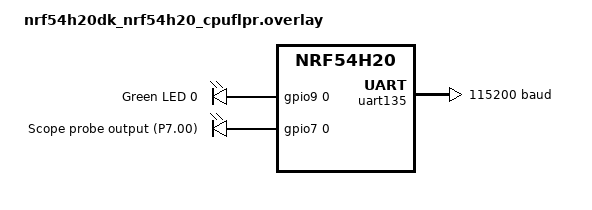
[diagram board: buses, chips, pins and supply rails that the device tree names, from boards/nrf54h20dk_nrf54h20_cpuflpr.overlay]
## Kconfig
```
# SPDX-License-Identifier: Apache-2.0

config BLINKY_BARE_METAL_GPIO
	bool "Toggle led0/probe0 by writing GPIO registers directly"
	help
	  When enabled, the blink loop drives led0 and probe0 by writing the
	  GPIO port's OUTSET/OUTCLR registers directly instead of calling
	  gpio_pin_toggle_dt(). Pin setup still uses the Zephyr GPIO API.

config BLINKY_PROBE_P7_00
	bool "Toggle P7.00 in the blink loop"
	default y
	help
	  When enabled, the blink loop toggles P7.00 (the probe0 pin) so it can
	  be probed. When disabled, P7.00 is left low. Independent of
	  BLINKY_PROBE_P9_00.

config BLINKY_FLPR_VIO
	bool "Drive P7.00 through FLPR's VIO"
	depends on SOC_NRF54H20_CPUFLPR && BLINKY_PROBE_P7_00
	help
	  Set this through SB_CONFIG_BLINKY_FLPR_VIO in sysbuild.conf, which
	  also routes P7.00 to FLPR's VIO in UICR; sysbuild overrides any value
	  set here. The blink loop then drives P7.00 with VIO CSR writes,
	  whichever toggle method is selected. P9.00 is unaffected.

config BLINKY_FLPR_VIO_DELAY_NOPS
	int "NOPs after each VIO write"
	depends on BLINKY_FLPR_VIO
	range 0 1024
	default 32
	help
	  Number of NOP instructions executed after each VIO write, i.e. once
	  for the high half and once for the low half of every pulse. Stretches
	  the few-nanosecond full-speed pulses so a logic analyzer can capture
	  them. With the default of 32, each half is roughly 100-175 ns. The
	  printed average per blink gives the actual period. Set to 0 for
	  full-speed toggling. Only affects the FLPR VIO path.

config BLINKY_PROBE_P9_00
	bool "Toggle P9.00 in the blink loop"
	help
	  When enabled, the blink loop toggles P9.00 so it can be probed. On
	  the nRF54H20 DK, P9.00 is the led0 pin, so LED0 flickers while the
	  loop runs. When disabled, P9.00 is left low. Independent of
	  BLINKY_PROBE_P7_00.

source "Kconfig.zephyr"
```

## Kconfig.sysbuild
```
# SPDX-License-Identifier: Apache-2.0

source "$(ZEPHYR_BASE)/share/sysbuild/Kconfig"

config BLINKY_FLPR_VIO
	bool "Drive P7.00 from FLPR's VIO instead of the GPIO controller"
	depends on SOC_NRF54H20_CPUFLPR
	help
	  Routes P7.00 to FLPR's VIO (CTRLSEL = VPR_GRC) through UICR, by
	  giving the vpr_launcher image a cpuflpr_vpr pinctrl entry for P7.00,
	  and sets CONFIG_BLINKY_FLPR_VIO in the application so the blink loop
	  drives P7.00 with VIO CSR writes. Also forces
	  CONFIG_BLINKY_PROBE_P7_00=y. While enabled, P7.00 cannot be driven
	  through gpio7.
```

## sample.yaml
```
sample:
  name: Blinky Sample
tests:
  sample.basic.blinky:
    tags:
      - LED
      - gpio
    filter: dt_enabled_alias_with_parent_compat("led0", "gpio-leds")
    depends_on: gpio
    harness: led
    platform_allow:
      - nrf54h20dk/nrf54h20/cpuapp
      - nrf54h20dk/nrf54h20/cpuppr
      - nrf54h20dk/nrf54h20/cpuflpr
    integration_platforms:
      - nrf54h20dk/nrf54h20/cpuapp
      - nrf54h20dk/nrf54h20/cpuppr
      - nrf54h20dk/nrf54h20/cpuflpr
```

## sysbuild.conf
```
# y: (cpuflpr only) route P7.00 to FLPR's VIO and drive it with VIO CSR writes.
# n: P7.00 is driven through the gpio7 controller.
SB_CONFIG_BLINKY_FLPR_VIO=y
```

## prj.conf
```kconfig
CONFIG_GPIO=y

# Build with -O2 instead of the default size optimization (-Os).
CONFIG_SPEED_OPTIMIZATIONS=y

# y: blink loop writes GPIO OUTSET/OUTCLR registers directly.
# n: blink loop uses gpio_pin_toggle_dt().
CONFIG_BLINKY_BARE_METAL_GPIO=y

# y: blink loop toggles P7.00 (probe0).
# n: P7.00 stays low.
CONFIG_BLINKY_PROBE_P7_00=y

# y: blink loop toggles P9.00 (the LED0 pin).
# n: P9.00/LED0 stays low.
CONFIG_BLINKY_PROBE_P9_00=n

# Explicitly ensure this image's peripheral usage (UART console, GPIO/LED,
# scope-probe pin) is emitted as UICR.PERIPHCONF entries rather than relying
# silently on the Kconfig default.
CONFIG_NRF_PERIPHCONF_GENERATE_ENTRIES=y

CONFIG_BLINKY_FLPR_VIO_DELAY_NOPS=10
```

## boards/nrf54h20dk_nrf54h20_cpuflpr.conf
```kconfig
# gpiote130 has no interrupt line on FLPR, and this app only drives outputs,
# so build the GPIO driver without GPIOTE-based interrupt support.
CONFIG_GPIO_NRFX_INTERRUPT=n

# The console is on uart135, whose IRQ cannot be routed to FLPR; keep the
# UART driver in polling mode.
CONFIG_UART_INTERRUPT_DRIVEN=n
CONFIG_UART_ASYNC_API=n
```

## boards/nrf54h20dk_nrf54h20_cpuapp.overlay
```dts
/* SPDX-License-Identifier: Apache-2.0 */

/ {
	aliases {
		probe0 = &probe0;
	};

	leds {
		/*
		 * Independent GPIO output, unrelated to led0, wired to pin
		 * P7.00 so it can be probed on an oscilloscope without
		 * disturbing the LED.
		 */
		probe0: probe_0 {
			gpios = <&gpio7 0 GPIO_ACTIVE_HIGH>;
			label = "Scope probe output (P7.00)";
		};
	};
};

&gpio7 {
	status = "okay";
};
```

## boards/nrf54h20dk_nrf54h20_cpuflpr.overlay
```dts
/* SPDX-License-Identifier: Apache-2.0 */

/ {
	/*
	 * The default FLPR console (uart120, P7.4/P7.7) is not wired to either
	 * DK serial port; uart135 (P1.10/P1.11) reaches the second one.
	 */
	chosen {
		zephyr,console = &uart135;
		zephyr,shell-uart = &uart135;
	};

	aliases {
		led0 = &led0;
		probe0 = &probe0;
	};

	reserved-memory {
		/*
		 * uart135 is a slow peripheral and cannot DMA from FLPR's RAM_21,
		 * so give it a buffer in RAM3x (mirrors cpurad_dma_region).
		 */
		cpuflpr_dma_region: memory@2fc13400 {
			compatible = "zephyr,memory-region";
			reg = <0x2fc13400 DT_SIZE_K(1)>;
			#memory-region-cells = <0>;
			zephyr,memory-region = "DMA_RAM3x_FLPR";
			zephyr,memory-attr = <DT_MEM_DMA>;
		};
	};

	leds {
		compatible = "gpio-leds";

		led0: led_0 {
			gpios = <&gpio9 0 GPIO_ACTIVE_HIGH>;
			label = "Green LED 0";
		};

		/*
		 * Independent GPIO output, unrelated to led0, wired to pin
		 * P7.00 so it can be probed on an oscilloscope without
		 * disturbing the LED.
		 */
		probe0: probe_0 {
			gpios = <&gpio7 0 GPIO_ACTIVE_HIGH>;
			label = "Scope probe output (P7.00)";
		};
	};
};

&uart120 {
	status = "disabled";
};

/* FLPR has no uart135 interrupt line, so the console runs in polling mode. */
&uart135 {
	status = "okay";
	memory-regions = <&cpuflpr_dma_region>;
	current-speed = <115200>;
	pinctrl-0 = <&uart135_default>;
	pinctrl-1 = <&uart135_sleep>;
	pinctrl-names = "default", "sleep";
};

&gpio9 {
	status = "okay";
};

&gpio7 {
	status = "okay";
};
```

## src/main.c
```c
/*
 * Copyright (c) 2016 Intel Corporation
 *
 * SPDX-License-Identifier: Apache-2.0
 */

/**
 * @file
 * @brief GPIO toggle-speed test for the nRF54H20 DK.
 *
 * Toggles P7.00 and/or P9.00 in a tight, interrupt-locked loop and reports the
 * loop time, so toggle rates can be compared across cores (cpuapp, cpuppr,
 * cpuflpr) and methods (Zephyr GPIO API, direct GPIO registers, FLPR VIO).
 */

#include <stdio.h>
#include <zephyr/kernel.h>
#include <zephyr/drivers/gpio.h>
#include <nrfx.h>

#if defined(CONFIG_BLINKY_FLPR_VIO)
/* VPR CSR headers only build on a VPR core, so include them for FLPR only. */
#include <hal/nrf_vpr_csr.h>
#include <hal/nrf_vpr_csr_vio.h>
#endif

/** Delay after boot before the timed loop starts, in milliseconds. */
#define STARTUP_DELAY_MS 10000

/** Number of loop iterations; each drives every enabled pin high then low. */
#define BLINK_COUNT 10000

/** Devicetree node of the led0 alias (P9.00 on the nRF54H20 DK). */
#define LED0_NODE DT_ALIAS(led0)

/** Devicetree node of the probe0 alias (P7.00 on the nRF54H20 DK). */
#define PROBE0_NODE DT_ALIAS(probe0)

#if !DT_NODE_EXISTS(LED0_NODE) || !DT_NODE_EXISTS(PROBE0_NODE)
#error "led0 and probe0 aliases are required; only the nRF54H20 DK targets are supported"
#endif

/** GPIO spec for P9.00 (LED0). */
static const struct gpio_dt_spec led = GPIO_DT_SPEC_GET(LED0_NODE, gpios);

/** GPIO spec for P7.00 (scope probe output). */
static const struct gpio_dt_spec probe = GPIO_DT_SPEC_GET(PROBE0_NODE, gpios);

/** @name Build configuration as compile-time constants
 * @{
 */
#define PROBE_P7   IS_ENABLED(CONFIG_BLINKY_PROBE_P7_00)     /**< Toggle P7.00. */
#define PROBE_P9   IS_ENABLED(CONFIG_BLINKY_PROBE_P9_00)     /**< Toggle P9.00. */
#define BARE_METAL IS_ENABLED(CONFIG_BLINKY_BARE_METAL_GPIO) /**< Use GPIO registers. */
#define FLPR_VIO   IS_ENABLED(CONFIG_BLINKY_FLPR_VIO)        /**< Drive P7.00 via VIO. */
/** @} */

BUILD_ASSERT(!PROBE_P7 || (DT_PROP(DT_GPIO_CTLR(PROBE0_NODE, gpios), port) == 7 &&
			   DT_GPIO_PIN(PROBE0_NODE, gpios) == 0),
	     "CONFIG_BLINKY_PROBE_P7_00 toggles probe0, which must be P7.00");
BUILD_ASSERT(!PROBE_P9 || (DT_PROP(DT_GPIO_CTLR(LED0_NODE, gpios), port) == 9 &&
			   DT_GPIO_PIN(LED0_NODE, gpios) == 0),
	     "CONFIG_BLINKY_PROBE_P9_00 toggles led0, which must be P9.00");

/* OUTSET/OUTCLR set the physical level, so an active-low pin would invert. */
BUILD_ASSERT(!BARE_METAL || !(DT_GPIO_FLAGS(LED0_NODE, gpios) & GPIO_ACTIVE_LOW),
	     "bare-metal mode assumes led0 is active-high");
BUILD_ASSERT(!BARE_METAL || !(DT_GPIO_FLAGS(PROBE0_NODE, gpios) & GPIO_ACTIVE_LOW),
	     "bare-metal mode assumes probe0 is active-high");

/**
 * @brief Register block of the GPIO port that a node's pin is on.
 * @param node Devicetree node with a @c gpios property.
 */
#define GPIO_REGS(node) ((NRF_GPIO_Type *)DT_REG_ADDR(DT_GPIO_CTLR(node, gpios)))

/**
 * @brief Port register mask of a node's pin.
 * @param node Devicetree node with a @c gpios property.
 */
#define GPIO_MASK(node) BIT(DT_GPIO_PIN(node, gpios))

/*
 * Per-pin edge functions. Each call produces one edge; the timed loop calls
 * *_high() then *_low() for every enabled pin. The implementation is chosen
 * at build time and always inlined, so the loop holds only the writes (plus
 * return-value checks in Zephyr API mode). In Zephyr API mode both functions
 * toggle; the pin starts low, so the first toggle is the rising edge.
 */

#if defined(CONFIG_BLINKY_BARE_METAL_GPIO)
/**
 * @brief Drive P9.00 high by writing its port's OUTSET register.
 * @return Always 0.
 */
static ALWAYS_INLINE int p9_high(void)
{
	GPIO_REGS(LED0_NODE)->OUTSET = GPIO_MASK(LED0_NODE);
	return 0;
}

/**
 * @brief Drive P9.00 low by writing its port's OUTCLR register.
 * @return Always 0.
 */
static ALWAYS_INLINE int p9_low(void)
{
	GPIO_REGS(LED0_NODE)->OUTCLR = GPIO_MASK(LED0_NODE);
	return 0;
}
#else
/**
 * @brief Rising edge on P9.00 through the Zephyr GPIO API.
 * @return 0 on success, negative errno from gpio_pin_toggle_dt() otherwise.
 */
static ALWAYS_INLINE int p9_high(void)
{
	return gpio_pin_toggle_dt(&led);
}

/**
 * @brief Falling edge on P9.00 through the Zephyr GPIO API.
 * @return 0 on success, negative errno from gpio_pin_toggle_dt() otherwise.
 */
static ALWAYS_INLINE int p9_low(void)
{
	return gpio_pin_toggle_dt(&led);
}
#endif

#if defined(CONFIG_BLINKY_FLPR_VIO)
/**
 * @brief VIO output mask used for P7.00.
 *
 * P7.00's VIO bit is not known here (the nrfx in NCS v3.4.1 has no nRF54H20
 * VIO pin map), so all 16 VIO outputs are driven. P7.00 is the only pin
 * routed to FLPR in UICR (CTRLSEL), so it is the only pin that moves.
 */
#define VIO_MASK 0xFFFFU

/** One NOP; LISTIFY() helper for VIO_DELAY(). */
#define VIO_NOP(i, _) arch_nop()

/**
 * @brief Fixed, unrolled run of CONFIG_BLINKY_FLPR_VIO_DELAY_NOPS NOPs.
 *
 * Executed after each VIO write to widen the pulses; unrolled so the delay
 * has an exact instruction count.
 */
#define VIO_DELAY() LISTIFY(CONFIG_BLINKY_FLPR_VIO_DELAY_NOPS, VIO_NOP, (;))

/**
 * @brief Enable FLPR's real-time peripherals and make the VIO pins low outputs.
 */
static void p7_prepare(void)
{
	nrf_vpr_csr_rtperiph_enable_set(true);
	nrf_vpr_csr_vio_out_set(0);
	nrf_vpr_csr_vio_dir_set(VIO_MASK);
}

/**
 * @brief Drive P7.00 high with a VIO CSR write, then run VIO_DELAY().
 * @return Always 0.
 */
static ALWAYS_INLINE int p7_high(void)
{
	nrf_vpr_csr_vio_out_set(VIO_MASK);
	VIO_DELAY();
	return 0;
}

/**
 * @brief Drive P7.00 low with a VIO CSR write, then run VIO_DELAY().
 * @return Always 0.
 */
static ALWAYS_INLINE int p7_low(void)
{
	nrf_vpr_csr_vio_out_set(0);
	VIO_DELAY();
	return 0;
}
#elif defined(CONFIG_BLINKY_BARE_METAL_GPIO)
/** @brief No preparation is needed for GPIO register writes. */
static void p7_prepare(void)
{
}

/**
 * @brief Drive P7.00 high by writing its port's OUTSET register.
 * @return Always 0.
 */
static ALWAYS_INLINE int p7_high(void)
{
	GPIO_REGS(PROBE0_NODE)->OUTSET = GPIO_MASK(PROBE0_NODE);
	return 0;
}

/**
 * @brief Drive P7.00 low by writing its port's OUTCLR register.
 * @return Always 0.
 */
static ALWAYS_INLINE int p7_low(void)
{
	GPIO_REGS(PROBE0_NODE)->OUTCLR = GPIO_MASK(PROBE0_NODE);
	return 0;
}
#else
/** @brief No preparation is needed for the Zephyr GPIO API. */
static void p7_prepare(void)
{
}

/**
 * @brief Rising edge on P7.00 through the Zephyr GPIO API.
 * @return 0 on success, negative errno from gpio_pin_toggle_dt() otherwise.
 */
static ALWAYS_INLINE int p7_high(void)
{
	return gpio_pin_toggle_dt(&probe);
}

/**
 * @brief Falling edge on P7.00 through the Zephyr GPIO API.
 * @return 0 on success, negative errno from gpio_pin_toggle_dt() otherwise.
 */
static ALWAYS_INLINE int p7_low(void)
{
	return gpio_pin_toggle_dt(&probe);
}
#endif

/** @name Pins written directly, bypassing the Zephyr GPIO driver
 * @{
 */
#define P9_DIRECT (PROBE_P9 && BARE_METAL)              /**< P9.00 via registers. */
#define P7_DIRECT (PROBE_P7 && (BARE_METAL || FLPR_VIO)) /**< P7.00 via registers/VIO. */
/** @} */

/**
 * @brief Set or clear the RETAIN bit of pins on one GPIO port.
 *
 * @param regs     GPIO port register block.
 * @param mask     Port pin mask.
 * @param retained true to set RETAIN (freeze the pins), false to clear it.
 */
static void retain_write(NRF_GPIO_Type *regs, uint32_t mask, bool retained)
{
	if (retained) {
		regs->RETAINSET = mask;
	} else {
		regs->RETAINCLR = mask;
	}
}

/**
 * @brief Set or clear RETAIN on every pin that is written directly.
 *
 * A pin with RETAIN set ignores output changes. The Zephyr driver clears
 * RETAIN around its own writes and may leave it set after configuring a pin
 * (it does for gpio9 when GPIOTE is used), so directly written pins are
 * released before the timed loop and re-retained afterwards.
 *
 * @param retained true to set RETAIN, false to clear it.
 */
static void set_direct_pins_retained(bool retained)
{
	if (P9_DIRECT) {
		retain_write(GPIO_REGS(LED0_NODE), GPIO_MASK(LED0_NODE), retained);
	}
	if (P7_DIRECT) {
		retain_write(GPIO_REGS(PROBE0_NODE), GPIO_MASK(PROBE0_NODE), retained);
	}
}

/**
 * @brief Configure a pin as a low output, printing any error.
 *
 * @param spec GPIO spec of the pin.
 * @param name Name used in error messages.
 * @return 0 on success, -ENODEV if the GPIO device is not ready, or a
 *         negative errno from gpio_pin_configure_dt().
 */
static int configure_output(const struct gpio_dt_spec *spec, const char *name)
{
	int ret;

	if (!gpio_is_ready_dt(spec)) {
		printf("Error: %s GPIO device %s not ready\n", name, spec->port->name);
		return -ENODEV;
	}

	ret = gpio_pin_configure_dt(spec, GPIO_OUTPUT_INACTIVE);
	if (ret < 0) {
		printf("Error %d: failed to configure %s\n", ret, name);
	}

	return ret;
}

/**
 * @brief Print the loop time, the average per blink and the counter frequency.
 *
 * @param cycles Kernel cycle count measured around the timed loop.
 */
static void print_timing(uint32_t cycles)
{
	/* Average from the raw cycle count, in hundredths of a nanosecond. */
	uint64_t avg_ns_x100 = k_cyc_to_ns_floor64(cycles) * 100U / BLINK_COUNT;

	printf("Blink loop took %u us\n", k_cyc_to_us_floor32(cycles));
	printf("Average per blink (loop time / %d, one high+low per pin): %u.%02u ns\n",
	       BLINK_COUNT, (unsigned int)(avg_ns_x100 / 100U),
	       (unsigned int)(avg_ns_x100 % 100U));
	printf("Cycle counter frequency (sys_clock_hw_cycles_per_sec): %u Hz\n",
	       (unsigned int)sys_clock_hw_cycles_per_sec());
}

/** Label for P7.00 in the startup line, noting when it is driven via VIO. */
#define P7_LABEL (FLPR_VIO ? " P7.00(FLPR VIO)" : " P7.00")

/**
 * @brief Configure the pins, run the timed toggle loop once and report timing.
 *
 * @return Always 0; errors are reported on the console.
 */
int main(void)
{
	const char *failed_pin = NULL;
	int ret = 0;
	int i;

	printf("Blinky starting on %s (%s GPIO, toggling:%s%s%s)\n", CONFIG_BOARD_TARGET,
	       BARE_METAL ? "bare-metal" : "Zephyr API",
	       PROBE_P7 ? P7_LABEL : "",
	       PROBE_P9 ? " P9.00" : "",
	       (PROBE_P7 || PROBE_P9) ? "" : " none");

	/* Both pins start as low outputs, whether or not they are probed. */
	if (configure_output(&led, "led0") < 0 || configure_output(&probe, "probe0") < 0) {
		return 0;
	}

	k_msleep(STARTUP_DELAY_MS);

	/* Untimed setup: release RETAIN on directly written pins, enable VIO. */
	set_direct_pins_retained(false);
	p7_prepare();

	/* Keep interrupts out of the timed loop. */
	unsigned int key = irq_lock();
	uint32_t start = k_cycle_get_32();

	/*
	 * Timed loop. Edges are always issued in this order: P9 high, P7 high,
	 * P9 low, P7 low. Disabled pins and the always-0 checks of the direct
	 * backends compile away.
	 */
	for (i = 0; i < BLINK_COUNT; i++) {
		if (PROBE_P9 && (ret = p9_high()) < 0) {
			failed_pin = "led0";
			break;
		}
		if (PROBE_P7 && (ret = p7_high()) < 0) {
			failed_pin = "probe0";
			break;
		}
		if (PROBE_P9 && (ret = p9_low()) < 0) {
			failed_pin = "led0";
			break;
		}
		if (PROBE_P7 && (ret = p7_low()) < 0) {
			failed_pin = "probe0";
			break;
		}
	}

	uint32_t cycles = k_cycle_get_32() - start;

	irq_unlock(key);

	/* Hand the pins back in the state the Zephyr driver leaves them. */
	set_direct_pins_retained(true);

	if (failed_pin != NULL) {
		printf("Error %d: failed to toggle %s (iteration %d)\n", ret, failed_pin, i);
		return 0;
	}

	print_timing(cycles);

	return 0;
}
```
